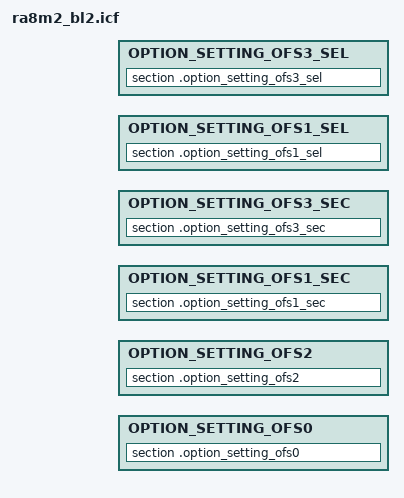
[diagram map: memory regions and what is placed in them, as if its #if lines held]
/*
 * Copyright (c) 2022 Arm Limited
 * Copyright (c) 2021 IAR Systems AB
 * Copyright (c) 2026 Renesas Electronics Corporation
 *
 * SPDX-License-Identifier: Apache-2.0
 */

/* IAR BL2 linker script for RA8M2. This file is run through the preprocessor.
 *
 * It is platform/ext/common/iar/tfm_common_bl2.icf plus three things the RA8M2 bootloader
 * needs and the common script has no hook for. It is the IAR counterpart of ra8m2_bl2.ld;
 * change the two together.
 *
 * 1. Option-setting (OFS) memory, the brick hazard (DECISIONS.md D002).
 *
 *    Each option group gets its own region and placement, exactly as FSP's generated
 *    fsp_gen.icf does. One region per group means the linker cannot merge them, so each word
 *    becomes its own small PT_LOAD.
 *
 *    WARNING: do not collapse these into one region spanning the whole OFS range. A single
 *    PT_LOAD across the range zero-fills the gaps, including defined option registers
 *    (D133), and flashing it bricks the part with no known recovery. The fill is invisible
 *    in the srec; only the program headers show it. check_ofs.py runs post-link on this
 *    image and is not optional. See region_defs.h, OPTION_SETTING_* block.
 *
 *    BL2 only: the secure and NS images are MCUboot-signed, imgtool needs a contiguous
 *    payload, and two images programming option memory would collide.
 *
 * 2. .ram_from_flash: inert on this part, kept rather than removed. r_mram applies no
 *    PLACE_IN_RAM_SECTION, so the section is empty in the linked image; MRAM stays readable
 *    while it is programmed. On RA6E1/RA6M5 it holds the r_flash_hp code-flash P/E routines;
 *    see ra6m5_bl2.icf, note 2. The startup init copies zero bytes here. See region_defs.h,
 *    "Secure RAM".
 *
 * 3. .ram_noinit: FSP keeps state there that must survive the C-runtime init
 *    (SystemCoreClock, g_clock_freq, g_protect_counters). SystemInit runs before the runtime
 *    init, so anything in zeroed memory is lost, which surfaced as FSP_ERR_FCLK
 *    (DESIGN.md §8.1). Marking it not-initialized gives the NOLOAD, never-zeroed behaviour
 *    that the GNU script gets by placing it outside the zero table.
 */

#include "region_defs.h"

do not initialize  { section .noinit };
/* See note 3. Never copied, never zeroed. */
do not initialize  { section .ram_noinit, section .ram_noinit* };

/* See note 2. */
initialize by copy { readwrite, ro section .ram_from_flash };

define block ER_CODE        with fixed order, alignment = 8 {
       section .intvec,
       readonly
       };
define block LR_CODE with fixed order, maximum size = BL2_CODE_SIZE {block ER_CODE};
place at address BL2_CODE_START {block LR_CODE};

define block TFM_SHARED_DATA with alignment = 32, size = BOOT_TFM_SHARED_DATA_SIZE { };
define block ER_DATA         with alignment = 32 {readwrite};

/* RAM-resident, see notes 2 and 3. */
/* Declared "rw section" so that ILINK copy-initialises it with the initialiser in FLASH; see
 * ra6m5_bl2.icf, ER_RAM_CODE. The RAM side stays inside DATA, as ra8m2_bl2.ld keeps
 * .ram_from_flash in the RAM region. */
define block ER_RAM_CODE     with alignment = 8 { rw section .ram_from_flash };
define block ER_RAM_NOINIT   with alignment = 4 { section .ram_noinit,
                                                  section .ram_noinit* };

#if defined (__ARM_FEATURE_CMSE) && (__ARM_FEATURE_CMSE == 3U)
define block ARM_LIB_STACK   with alignment = 32, size = BL2_MSP_STACK_SIZE - 0x8 { };
define block STACKSEAL with size = 0x8 { };
#else
define block ARM_LIB_STACK   with alignment = 32, size = BL2_MSP_STACK_SIZE { };
#endif /* #if defined (__ARM_FEATURE_CMSE) && (__ARM_FEATURE_CMSE == 3U) */
define block HEAP            with alignment = 8, size = BL2_HEAP_SIZE { };
define block ARM_LIB_HEAP    with alignment = 8, size = BL2_HEAP_SIZE { };
define overlay HEAP_OVL      {block HEAP};
define overlay HEAP_OVL      {block ARM_LIB_HEAP};
keep {block TFM_SHARED_DATA, block ER_DATA, block ARM_LIB_STACK,
      block HEAP, block ARM_LIB_HEAP, block ER_RAM_CODE, block ER_RAM_NOINIT};

if (isdefinedsymbol(__USE_DLIB_PERTHREAD))
{
  // Required in a multi-threaded application
  initialize by copy with packing = none { section __DLIB_PERTHREAD };
}

define block DATA with fixed order, maximum size = BL2_DATA_SIZE {
       block TFM_SHARED_DATA,
       block ER_DATA,
       block ER_RAM_CODE,
       block ER_RAM_NOINIT,
       block ARM_LIB_STACK,
#if defined (__ARM_FEATURE_CMSE) && (__ARM_FEATURE_CMSE == 3U)
       block STACKSEAL,
#endif /* #if defined (__ARM_FEATURE_CMSE) && (__ARM_FEATURE_CMSE == 3U) */
       overlay HEAP_OVL
};
place at address BOOT_TFM_SHARED_DATA_BASE {block DATA};

/* ---------------------------------------------------------------------------
 * Option-setting memory. See note 1. One region per group - never merge these.
 * --------------------------------------------------------------------------- */
define region OPTION_SETTING_OFS0 = mem:[from OPTION_SETTING_OFS0_START size OPTION_SETTING_OFS0_LENGTH];
define region OPTION_SETTING_OFS2 = mem:[from OPTION_SETTING_OFS2_START size OPTION_SETTING_OFS2_LENGTH];
define region OPTION_SETTING_OFS1_SEC = mem:[from OPTION_SETTING_OFS1_SEC_START size OPTION_SETTING_OFS1_SEC_LENGTH];
define region OPTION_SETTING_OFS3_SEC = mem:[from OPTION_SETTING_OFS3_SEC_START size OPTION_SETTING_OFS3_SEC_LENGTH];
define region OPTION_SETTING_OFS1_SEL = mem:[from OPTION_SETTING_OFS1_SEL_START size OPTION_SETTING_OFS1_SEL_LENGTH];
define region OPTION_SETTING_OFS3_SEL = mem:[from OPTION_SETTING_OFS3_SEL_START size OPTION_SETTING_OFS3_SEL_LENGTH];

keep {section .option_setting_ofs0,
      section .option_setting_ofs2,
      section .option_setting_ofs1_sec,
      section .option_setting_ofs3_sec,
      section .option_setting_ofs1_sel,
      section .option_setting_ofs3_sel };

place in OPTION_SETTING_OFS0 { section .option_setting_ofs0 };
place in OPTION_SETTING_OFS2 { section .option_setting_ofs2 };
place in OPTION_SETTING_OFS1_SEC { section .option_setting_ofs1_sec };
place in OPTION_SETTING_OFS3_SEC { section .option_setting_ofs3_sec };
place in OPTION_SETTING_OFS1_SEL { section .option_setting_ofs1_sel };
place in OPTION_SETTING_OFS3_SEL { section .option_setting_ofs3_sel };
